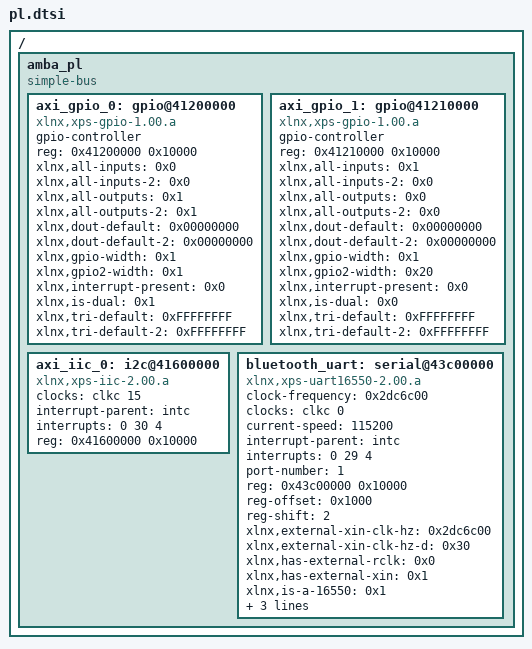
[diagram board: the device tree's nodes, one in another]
/*
 * CAUTION: This file is automatically generated by Xilinx.
 * Version:  
 * Today is: Fri Oct 27 21:31:34 2017
*/


/ {
	amba_pl: amba_pl {
		#address-cells = <1>;
		#size-cells = <1>;
		compatible = "simple-bus";
		ranges ;
		axi_gpio_0: gpio@41200000 {
			#gpio-cells = <2>;
			compatible = "xlnx,xps-gpio-1.00.a";
			gpio-controller ;
			reg = <0x41200000 0x10000>;
			xlnx,all-inputs = <0x0>;
			xlnx,all-inputs-2 = <0x0>;
			xlnx,all-outputs = <0x1>;
			xlnx,all-outputs-2 = <0x1>;
			xlnx,dout-default = <0x00000000>;
			xlnx,dout-default-2 = <0x00000000>;
			xlnx,gpio-width = <0x1>;
			xlnx,gpio2-width = <0x1>;
			xlnx,interrupt-present = <0x0>;
			xlnx,is-dual = <0x1>;
			xlnx,tri-default = <0xFFFFFFFF>;
			xlnx,tri-default-2 = <0xFFFFFFFF>;
		};
		axi_gpio_1: gpio@41210000 {
			#gpio-cells = <2>;
			compatible = "xlnx,xps-gpio-1.00.a";
			gpio-controller ;
			reg = <0x41210000 0x10000>;
			xlnx,all-inputs = <0x1>;
			xlnx,all-inputs-2 = <0x0>;
			xlnx,all-outputs = <0x0>;
			xlnx,all-outputs-2 = <0x0>;
			xlnx,dout-default = <0x00000000>;
			xlnx,dout-default-2 = <0x00000000>;
			xlnx,gpio-width = <0x1>;
			xlnx,gpio2-width = <0x20>;
			xlnx,interrupt-present = <0x0>;
			xlnx,is-dual = <0x0>;
			xlnx,tri-default = <0xFFFFFFFF>;
			xlnx,tri-default-2 = <0xFFFFFFFF>;
		};
		axi_iic_0: i2c@41600000 {
			#address-cells = <1>;
			#size-cells = <0>;
			clock-names = "ref_clk";
			clocks = <&clkc 15>;
			compatible = "xlnx,xps-iic-2.00.a";
			interrupt-parent = <&intc>;
			interrupts = <0 30 4>;
			reg = <0x41600000 0x10000>;
		};
		bluetooth_uart: serial@43c00000 {
			clock-frequency = <0x2dc6c00>;
			clock-names = "ref_clk";
			clocks = <&clkc 0>;
			compatible = "xlnx,xps-uart16550-2.00.a", "ns16550a";
			current-speed = <115200>;
			device_type = "serial";
			interrupt-parent = <&intc>;
			interrupts = <0 29 4>;
			port-number = <1>;
			reg = <0x43c00000 0x10000>;
			reg-offset = <0x1000>;
			reg-shift = <2>;
			xlnx,external-xin-clk-hz = <0x2dc6c00>;
			xlnx,external-xin-clk-hz-d = <0x30>;
			xlnx,has-external-rclk = <0x0>;
			xlnx,has-external-xin = <0x1>;
			xlnx,is-a-16550 = <0x1>;
			xlnx,s-axi-aclk-freq-hz-d = "100.0";
			xlnx,use-modem-ports = <0x1>;
			xlnx,use-user-ports = <0x1>;
		};
	};
};
